AUTOSAR XML (schema 00048)
package /Eps_Repository/ActiveReturn/ActiveReturn_L_Adapter
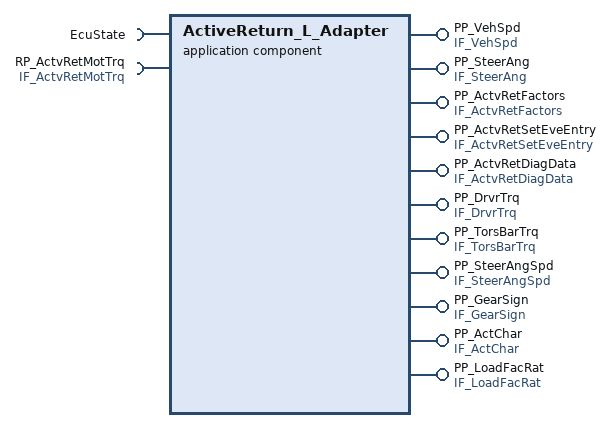
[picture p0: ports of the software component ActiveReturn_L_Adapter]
  application sw component type ActiveReturn_L_Adapter
    provide port PP_VehSpd: provided-com-specs=[{data-element=AbsAvgVehSpd, init-value=0}, {data-element=AbsMaxSafeVehSpd, init-value=0}], provided-interface=IF_VehSpd
    provide port PP_SteerAng: provided-com-specs=[{data-element=SteerAng, init-value=0}, {data-element=SteerAngSt, init-value=0}], provided-interface=IF_SteerAng
    provide port PP_ActvRetFactors: provided-com-specs=[{data-element=ActvRetFuncFac, init-value=0}, {data-element=ActvRetSpdFac, init-value=0}], provided-interface=IF_ActvRetFactors
    require port EcuState: required-interface=EcuState
    provide port PP_ActvRetSetEveEntry: server-com-spec=Set_ActvRetEntry, provided-interface=IF_ActvRetSetEveEntry
    provide port PP_ActvRetDiagData: server-com-spec=Set_ActvRetDiagData, provided-interface=IF_ActvRetDiagData
    require port RP_ActvRetMotTrq: nonqueued-receiver-com-spec{data-element=ActvRetMotTrq, init-value=0}, required-interface=IF_ActvRetMotTrq
    6 x provide port:
      PP_DrvrTrq: nonqueued-sender-com-spec{data-element=DrvrTrq, init-value=0}, provided-interface=IF_DrvrTrq
      PP_TorsBarTrq: nonqueued-sender-com-spec{data-element=TorsBarTrq, init-value=0}, provided-interface=IF_TorsBarTrq
      PP_SteerAngSpd: nonqueued-sender-com-spec{data-element=SteerAngSpd, init-value=0}, provided-interface=IF_SteerAngSpd
      PP_GearSign: nonqueued-sender-com-spec{data-element=GearSign, init-value=0}, provided-interface=IF_GearSign
      PP_ActChar: nonqueued-sender-com-spec{data-element=ActChar, init-value=0}, provided-interface=IF_ActChar
      PP_LoadFacRat: nonqueued-sender-com-spec{data-element=LoadFacRat, init-value=1}, provided-interface=IF_LoadFacRat
    behavior IB_ActiveReturn_L_Adapter: data-type-mapping=[DTMS_ActvRet_L_Adpr, DTMS_ActvRetChk], handle-termination-and-restart=NO-SUPPORT
      4 x timing event:
        TE_ActiveReturn_L_Adapter_100msEnd: period=0.1
          disabled-mode:
            EcuState.ApplicationModes.ApplicationInit
            EcuState.ApplicationModes.ApplicationOff
            EcuState.ApplicationModes.EcuInit
            EcuState.ApplicationModes.PostRun
        TE_ActiveReturn_L_Adapter_100msStart: start-on-event=ActvRet_L_Adpr_100msStrt, period=0.1
          disabled-mode:
            EcuState.ApplicationModes.ApplicationInit
            EcuState.ApplicationModes.ApplicationOff
            EcuState.ApplicationModes.EcuInit
            EcuState.ApplicationModes.PostRun
        TE_ActiveReturn_L_Adapter_10msEnd: start-on-event=ActvRet_L_Adpr_10msEnd, period=0.01
          disabled-mode:
            EcuState.ApplicationModes.ApplicationInit
            EcuState.ApplicationModes.ApplicationOff
            EcuState.ApplicationModes.EcuInit
            EcuState.ApplicationModes.PostRun
        TE_ActiveReturn_L_Adapter_10msStart: start-on-event=ActvRet_L_Adpr_10msStrt, period=0.01
          disabled-mode:
            EcuState.ApplicationModes.ApplicationInit
            EcuState.ApplicationModes.ApplicationOff
            EcuState.ApplicationModes.EcuInit
            EcuState.ApplicationModes.PostRun
      operation invoked event OIE_ActiveReturn_L_Adapter_SetEventEntry: start-on-event=ActvRet_L_Adpr_SetEveEntry, operation=PP_ActvRetSetEveEntry.Set_ActvRetEntry
      operation invoked event OIE_ActiveReturn_L_Adapter_DiagData: start-on-event=ActvRet_L_Adpr_DiagData, operation=PP_ActvRetDiagData.Set_ActvRetDiagData
      5 x runnable:
        ActvRet_L_Adpr_10msStrt: symbol=ActRetLAdapter_10msStart
          data-send-points:
            12 x access:
              DSP_PP_DrvrTrq_DrvrTrq: accessed-variable=PP_DrvrTrq.DrvrTrq
              DSP_PP_TorsBarTrq_TorsBarTrq: accessed-variable=PP_TorsBarTrq.TorsBarTrq
              DSP_PP_SteerAngSpd_SteerAngSpd: accessed-variable=PP_SteerAngSpd.SteerAngSpd
              DSP_PP_GearSign_GearSign: accessed-variable=PP_GearSign.GearSign
              DSP_PP_ActChar_ActChar: accessed-variable=PP_ActChar.ActChar
              DSP_PP_LoadFacRat_LoadFacRat: accessed-variable=PP_LoadFacRat.LoadFacRat
              DSP_PP_SteerAng_SteerAng: accessed-variable=PP_SteerAng.SteerAng
              DSP_PP_SteerAng_SteerAngSt: accessed-variable=PP_SteerAng.SteerAngSt
              DSP_PP_ActvRetFactors_ActvRetFuncFac: accessed-variable=PP_ActvRetFactors.ActvRetFuncFac
              DSP_PP_ActvRetFactors_ActvRetSpdFac: accessed-variable=PP_ActvRetFactors.ActvRetSpdFac
              DSP_PP_VehSpd_AbsAvgVehSpd: accessed-variable=PP_VehSpd.AbsAvgVehSpd
              DSP_PP_VehSpd_AbsMaxSafeVehSpd: accessed-variable=PP_VehSpd.AbsMaxSafeVehSpd
        ActvRet_L_Adpr_10msEnd: symbol=ActRetLAdapter_10msEnd
          data-receive-point-by-arguments:
            access DRP_RP_ActvRetMotTrq_ActvRetMotTrq: accessed-variable=RP_ActvRetMotTrq.ActvRetMotTrq
        ActvRet_L_Adpr_100msStrt: symbol=ActRetLAdapter_100msStart
          data-send-points:
            access DSP_PP_VehSpd_AbsAvgVehSpd: accessed-variable=PP_VehSpd.AbsAvgVehSpd
        ActvRet_L_Adpr_SetEveEntry: symbol=ActRetLAdapter_SetEventEntry
        ActvRet_L_Adpr_DiagData: symbol=ActRetLAdapter_DiagData
package /Eps_Repository/ActiveReturn/ActiveReturn_L_Adapter/Interfaces
  mode declaration group ApplicationModes: category=ALPHABETIC_ORDER, initial-mode=EcuInit
    8 x mode:
      ApplicationInit
      ApplicationOff
      EcuInit
      Error
      FailOp
      Normal
      PostRun
      Production
  mode switch interface EcuState
    mode group ApplicationModes: type=ApplicationModes
  11 x sender receiver interface:
    IF_AbsDrvrTrq: invalidation-policy{data-element=AbsDrvrTrq, handle-invalid=KEEP}
      data AbsDrvrTrq: sw-addr-method=DAMOS_RAM_DTA, sw-calibration-access=READ-ONLY, type=ADT_AbsDrvrTrq
    IF_AbsSteerAng: invalidation-policy{data-element=AbsSteerAng, handle-invalid=KEEP}
      data AbsSteerAng: sw-addr-method=DAMOS_RAM_DTA, sw-calibration-access=READ-ONLY, type=ADT_AbsSteerAng
    IF_DrvrTrq: invalidation-policy{data-element=DrvrTrq, handle-invalid=KEEP}
      data DrvrTrq: sw-addr-method=DAMOS_RAM_DTA, sw-calibration-access=READ-ONLY, type=ADT_DrvrTrq
    IF_GearSign: invalidation-policy{data-element=GearSign, handle-invalid=KEEP}
      data GearSign: sw-addr-method=DAMOS_RAM_DTA, sw-calibration-access=READ-ONLY, type=ADT_GearSign
    IF_LoadFacRat: invalidation-policy{data-element=LoadFacRat, handle-invalid=KEEP}
      data LoadFacRat: sw-addr-method=DAMOS_RAM_DTA, sw-calibration-access=READ-ONLY, type=ADT_LoadFacRat
    IF_ActChar
      data ActChar: sw-calibration-access=READ-ONLY, type=ADT_ActChar
    IF_SteerAngSpd: invalidation-policy{data-element=SteerAngSpd, handle-invalid=KEEP}
      data SteerAngSpd: sw-addr-method=DAMOS_RAM_DTA, sw-calibration-access=READ-ONLY, type=ADT_SteerAngSpd
    IF_TorsBarTrq: invalidation-policy{data-element=TorsBarTrq, handle-invalid=KEEP}
      data TorsBarTrq: sw-addr-method=DAMOS_RAM_DTA, sw-calibration-access=READ-ONLY, type=ADT_TorsBarTrq
    IF_ActvRetFactors: invalidation-policys=[{data-element=ActvRetFuncFac, handle-invalid=KEEP}, {data-element=ActvRetSpdFac, handle-invalid=KEEP}]
      data ActvRetFuncFac: sw-addr-method=DAMOS_RAM_DTA, sw-calibration-access=READ-ONLY, type=ADT_ActvRetFuncFac
      data ActvRetSpdFac: sw-addr-method=DAMOS_RAM_DTA, sw-calibration-access=READ-ONLY, type=ADT_ActvRetSpdFac
    IF_SteerAng: invalidation-policys=[{data-element=SteerAng, handle-invalid=KEEP}, {data-element=SteerAngSt, handle-invalid=KEEP}]
      data SteerAng: sw-addr-method=DAMOS_RAM_DTA, sw-calibration-access=READ-ONLY, type=ADT_SteerAng
      data SteerAngSt: sw-addr-method=DAMOS_RAM_DTA, sw-calibration-access=READ-ONLY, type=ADT_SteerAngSt
    IF_VehSpd: invalidation-policys=[{data-element=AbsAvgVehSpd, handle-invalid=KEEP}, {data-element=AbsMaxSafeVehSpd, handle-invalid=KEEP}]
      data AbsAvgVehSpd: sw-addr-method=DAMOS_RAM_DTA, sw-calibration-access=READ-ONLY, type=ADT_AbsAvgVehSpd
      data AbsMaxSafeVehSpd: sw-addr-method=DAMOS_RAM_DTA, sw-calibration-access=READ-ONLY, type=ADT_AbsMaxSafeVehSpd
package /Eps_Repository/ActiveReturn/ActiveReturn_L_Adapter/ApplicationDataTypes
  14 x app type, all with category=VALUE:
    ADT_AbsDrvrTrq: compu {phys=raw/1024; unit NwtMtr}, range phys 0..25, raw 0..25600
    ADT_DrvrTrq: compu {phys=raw/1024; unit NwtMtr}, range phys -25..25, raw -25600..25600
    ADT_TorsBarTrq: compu {phys=raw/1024; unit NwtMtr}, range phys -25..25, raw -25600..25600
    ADT_SteerAngSt: compu {0=CM_SYMBOL_RP_INVALID, 1=CM_SYMBOL_RP_RAW, 2=CM_SYMBOL_RP_EXACTLY, 3=CM_SYMBOL_RP_INITWAIT}, range phys 0..3, raw 0..3
    ADT_SteerAngSpd: compu {phys=raw*0.125}, range phys -1500..1500, raw -12000..12000
    ADT_AbsAvgVehSpd: compu {phys=raw/64; unit KiloMtrPerHr}, range phys 0..500, raw 0..32000
    ADT_AbsMaxSafeVehSpd: compu {phys=raw/64; unit KiloMtrPerHr}, range phys 0..500, raw 0..32000
    ADT_AbsSteerAng: compu {phys=raw*0.1; unit DegAngle}, range phys 0..1000, raw 0..10000
    ADT_SteerAng: compu {phys=raw*0.1; unit DegAngle}, range phys -1000..1000, raw -10000..10000
    ADT_GearSign: compu {phys=raw}, range phys -1..1, raw -1..1
    ADT_ActvRetFuncFac: compu {phys=raw/1024}, range phys 0..1, raw 0..1024
    ADT_ActvRetSpdFac: compu {phys=raw/1024}, range phys 0..1, raw 0..1024
    ADT_ActChar: compu {phys=raw}, range phys 0..2, raw 0..2, invalid-value=255, unit=NoUnit
    ADT_LoadFacRat: compu {phys=raw/1024}, range phys 0..3, raw 0..3072
package /Eps_Repository/ActiveReturn/ActiveReturn_L_Adapter/ImplementationDataTypes
  14 x impl type, all with category=TYPE_REFERENCE:
    IDT_AbsDrvrTrq: range phys 0..25, raw 0..25600, implementation-data-type=uint16, invalid-value=Value:65535
    IDT_DrvrTrq: range phys -25..25, raw -25600..25600, implementation-data-type=sint16, invalid-value=Value:32767
    IDT_TorsBarTrq: range phys -25..25, raw -25600..25600, implementation-data-type=sint16, invalid-value=Value:32767
    IDT_SteerAngSt: range phys 0..3, raw 0..3, implementation-data-type=uint8, invalid-value=Value:255
    IDT_SteerAngSpd: range phys -1500..1500, raw -12000..12000, implementation-data-type=sint16, invalid-value=Value:32767
    IDT_AbsAvgVehSpd: range phys 0..500, raw 0..32000, implementation-data-type=uint16, invalid-value=Value:65535
    IDT_AbsMaxSafeVehSpd: range phys 0..500, raw 0..32000, implementation-data-type=uint16, invalid-value=Value:65535
    IDT_AbsSteerAng: range phys 0..1000, raw 0..10000, implementation-data-type=uint16, invalid-value=Value:65535
    IDT_SteerAng: range phys -1000..1000, raw -10000..10000, implementation-data-type=sint16, invalid-value=Value:32767
    IDT_GearSign: range phys -1..1, raw -1..1, implementation-data-type=sint8, invalid-value=Value:127
    IDT_ActvRetFuncFac: range phys 0..1, raw 0..1024, implementation-data-type=uint16, invalid-value=Value:65535
    IDT_ActvRetSpdFac: range phys 0..1, raw 0..1024, implementation-data-type=uint16, invalid-value=Value:65535
    IDT_ActChar: range phys 0..2, raw 0..2, implementation-data-type=uint8
    IDT_LoadFacRat: range phys 0..3, raw 0..3072, implementation-data-type=uint16, invalid-value=Value:65535
package /Eps_Repository/ActiveReturn/ActiveReturn_L_Adapter/CompuMethods
  compu method CM_ARFACT: phys=raw/16384
  compu method CM_MMOT: phys=raw/1024; unit NwtMtr
  compu method CM_MMOT_RSH6: phys=raw/64; unit NwtMtr
  compu method CM_RIGHTSH15NP: phys=raw/32768
  compu method CM_RIGHTSH16NP: phys=raw/65536
  compu method CM_RIGHTSH20NP: phys=raw/1048576
  compu method CM_RIGHTSH7NP: phys=raw/128
  compu method CM_TBT_RSH4: phys=raw*0.0625; unit NwtMtr
package /Eps_Repository/ActiveReturn/ActiveReturn_L_Adapter/DataTypeMappingSets
  data type mapping set DTMS_ActvRet_L_Adpr: mode-request-type-map{implementation-data-type=uint8, mode-group=ApplicationModes}
    data-type-maps:
      application-data-type=ADT_AbsDrvrTrq, implementation-data-type=IDT_AbsDrvrTrq
      application-data-type=ADT_DrvrTrq, implementation-data-type=IDT_DrvrTrq
      application-data-type=ADT_TorsBarTrq, implementation-data-type=IDT_TorsBarTrq
      application-data-type=ADT_SteerAngSt, implementation-data-type=IDT_SteerAngSt
      application-data-type=ADT_SteerAngSpd, implementation-data-type=IDT_SteerAngSpd
      application-data-type=ADT_AbsAvgVehSpd, implementation-data-type=IDT_AbsAvgVehSpd
      application-data-type=ADT_AbsMaxSafeVehSpd, implementation-data-type=IDT_AbsMaxSafeVehSpd
      application-data-type=ADT_AbsSteerAng, implementation-data-type=IDT_AbsSteerAng
      application-data-type=ADT_SteerAng, implementation-data-type=IDT_SteerAng
      application-data-type=ADT_GearSign, implementation-data-type=IDT_GearSign
      application-data-type=ADT_ActvRetFuncFac, implementation-data-type=IDT_ActvRetFuncFac
      application-data-type=ADT_ActvRetSpdFac, implementation-data-type=IDT_ActvRetSpdFac
      application-data-type=ADT_ActChar, implementation-data-type=IDT_ActChar
      application-data-type=ADT_LoadFacRat, implementation-data-type=IDT_LoadFacRat
package /Eps_Repository/ActiveReturn/ActiveReturn_L_Adapter/SWAddrMethod
  sw addr method DAMOS_RAM_DTA: memory-allocation-keyword-policy=ADDR-METHOD-SHORT-NAME, section-initialization-policy=INIT, section-type=VAR
